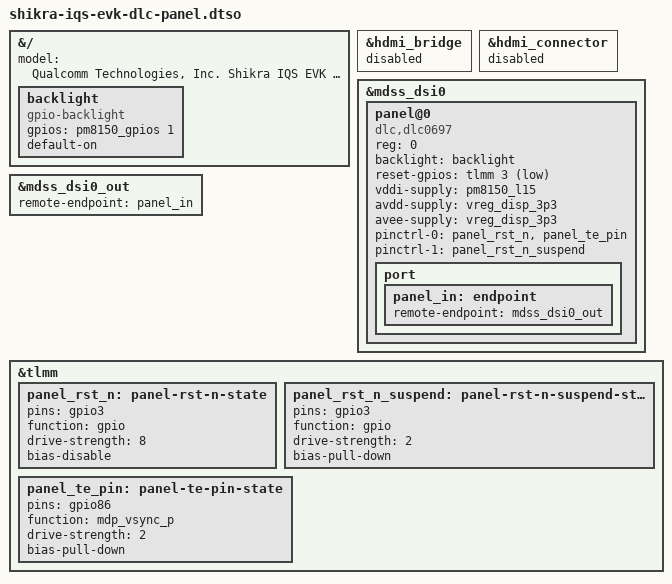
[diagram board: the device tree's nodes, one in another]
// SPDX-License-Identifier: BSD-3-Clause
/*
 * Copyright (c) Qualcomm Technologies, Inc. and/or its subsidiaries.
 */

/dts-v1/;
/plugin/;

#include <dt-bindings/gpio/gpio.h>

&{/} {
	model = "Qualcomm Technologies, Inc. Shikra IQS EVK DLC Panel";

	backlight: backlight {
		compatible = "gpio-backlight";
		gpios = <&pm8150_gpios 1 GPIO_ACTIVE_HIGH>;
		default-on;
	};
};

&hdmi_bridge {
	status = "disabled";
};

&hdmi_connector {
	status = "disabled";
};

&mdss_dsi0 {
	#address-cells = <1>;
	#size-cells = <0>;

	panel@0 {
		compatible = "dlc,dlc0697", "ilitek,ili7807s";
		reg = <0>;
		backlight = <&backlight>;
		reset-gpios = <&tlmm 3 GPIO_ACTIVE_LOW>;
		vddi-supply = <&pm8150_l15>;
		avdd-supply = <&vreg_disp_3p3>;
		avee-supply = <&vreg_disp_3p3>;
		pinctrl-0 = <&panel_rst_n &panel_te_pin>;
		pinctrl-1 = <&panel_rst_n_suspend>;
		pinctrl-names = "default", "sleep";

		port {
			panel_in: endpoint {
				remote-endpoint = <&mdss_dsi0_out>;
			};
		};
	};
};

&mdss_dsi0_out {
	remote-endpoint = <&panel_in>;
};

&tlmm {
	panel_rst_n: panel-rst-n-state {
		pins = "gpio3";
		function = "gpio";
		drive-strength = <8>;
		bias-disable;
	};

	panel_rst_n_suspend: panel-rst-n-suspend-state {
		pins = "gpio3";
		function = "gpio";
		drive-strength = <2>;
		bias-pull-down;
	};

	panel_te_pin: panel-te-pin-state {
		pins = "gpio86";
		function = "mdp_vsync_p";
		drive-strength = <2>;
		bias-pull-down;
	};
};
